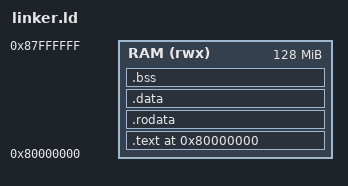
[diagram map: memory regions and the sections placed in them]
OUTPUT_ARCH(riscv)
ENTRY(_start)

MEMORY
{
    RAM (rwx) : ORIGIN = 0x80000000, LENGTH = 128M
}

SECTIONS
{
    . = ORIGIN(RAM);

    .text : ALIGN(4)
    {
        KEEP(*(.text.init))
        *(.text .text.*)
    } > RAM

    .rodata : ALIGN(8)
    {
        *(.rodata .rodata.*)
    } > RAM

    .data : ALIGN(8)
    {
        *(.data .data.*)
        *(.sdata .sdata.*)
    } > RAM

    .bss (NOLOAD) : ALIGN(8)
    {
        *(.bss .bss.*)
        *(.sbss .sbss.*)
        *(COMMON)
    } > RAM

    . = ALIGN(16);
    . += 16K;
    _stack_top = .;
}
